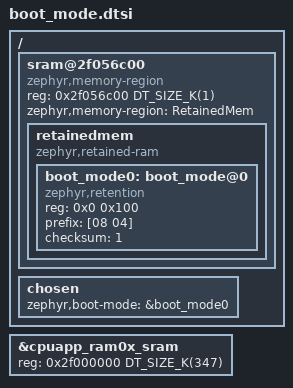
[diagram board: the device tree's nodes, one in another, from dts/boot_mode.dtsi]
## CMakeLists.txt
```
# Copyright (c) 2026 Nordic Semiconductor ASA
# SPDX-License-Identifier: LicenseRef-Nordic-5-Clause

cmake_minimum_required(VERSION 3.20.0)

find_package(Zephyr REQUIRED HINTS $ENV{ZEPHYR_BASE})
project(nrf9251_smp_single_slot)

target_sources(app PRIVATE src/main.c)
```

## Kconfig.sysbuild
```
#
# Copyright (c) 2026 Nordic Semiconductor ASA
#
# SPDX-License-Identifier: LicenseRef-Nordic-5-Clause
#

config MCUBOOT_SIGNATURE_USING_ITS
	default y if SOC_SERIES_NRF92

config BOOT_SIGNATURE_TYPE_PURE
	default y if SOC_SERIES_NRF92 && BOOT_SIGNATURE_TYPE_ED25519

choice BOOT_SIGNATURE_TYPE
	default BOOT_SIGNATURE_TYPE_ED25519 if SOC_SERIES_NRF92
endchoice

source "share/sysbuild/Kconfig"
```

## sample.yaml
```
##
# Copyright (c) 2026 Nordic Semiconductor ASA
#
# SPDX-License-Identifier: LicenseRef-Nordic-5-Clause
#

sample:
  name: nRF9251 SMP single-slot DFU sample
  description: Single-slot application update using MCUboot serial recovery over UART
common:
  sysbuild: true
  harness: console
  harness_config:
    type: one_line
    regex:
      - "nRF9251 SMP single-slot sample, firmware version"
  tags:
    - ci_samples_dfu
tests:
  sample.dfu.nrf9251_smp_single_slot:
    build_only: true
    platform_allow:
      - nrf9251dk/nrf9251/cpuapp
    integration_platforms:
      - nrf9251dk/nrf9251/cpuapp
```

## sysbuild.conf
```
# Copyright (c) 2026 Nordic Semiconductor ASA
# SPDX-License-Identifier: LicenseRef-Nordic-5-Clause

SB_CONFIG_BOOTLOADER_MCUBOOT=y
SB_CONFIG_MCUBOOT_MODE_SINGLE_APP=y

# Verify images with public keys provisioned to ITS (BL_PUBKEY slots), same as nRF54H20.
SB_CONFIG_MCUBOOT_SIGNATURE_USING_ITS=y
SB_CONFIG_BOOT_SIGNATURE_TYPE_ED25519=y
SB_CONFIG_BOOT_SIGNATURE_TYPE_PURE=y
```

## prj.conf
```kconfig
# Copyright (c) 2026 Nordic Semiconductor ASA
# SPDX-License-Identifier: LicenseRef-Nordic-5-Clause

CONFIG_BOOTLOADER_MCUBOOT=y

CONFIG_GPIO=y

CONFIG_LOG=y
CONFIG_LOG_MODE_IMMEDIATE=y

CONFIG_REBOOT=y

# Retained boot mode, shared with MCUboot via dts/boot_mode.dtsi.
CONFIG_RETAINED_MEM=y
CONFIG_RETAINED_MEM_ZEPHYR_RAM=y
CONFIG_RETENTION=y
CONFIG_RETENTION_BOOT_MODE=y

# Minimal SMP server: accept MCUmgr "os reset" with boot mode so a host MCU can
# request MCUboot serial recovery while the application is running.
# No image group: with a single slot, MCUboot serial recovery performs the update.
CONFIG_NET_BUF=y
CONFIG_ZCBOR=y
CONFIG_CRC=y
CONFIG_BASE64=y
CONFIG_MCUMGR=y
CONFIG_UART_MCUMGR=y
CONFIG_MCUMGR_TRANSPORT_UART=y
CONFIG_MCUMGR_GRP_OS=y
CONFIG_MCUMGR_GRP_OS_RESET_BOOT_MODE=y
```

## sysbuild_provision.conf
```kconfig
#
# Copyright (c) 2026 Nordic Semiconductor ASA
#
# SPDX-License-Identifier: LicenseRef-Nordic-5-Clause
#
# Optional: generate build/<app>/keyfile.json from the signing key and provision it on
# ``west flash`` (see README). Do not use in production.

SB_CONFIG_MCUBOOT_GENERATE_DEFAULT_KEY_FILE=y
```

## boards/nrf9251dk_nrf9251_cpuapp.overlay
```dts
/*
 * Copyright (c) 2026 Nordic Semiconductor ASA
 * SPDX-License-Identifier: LicenseRef-Nordic-5-Clause
 */

#include "../dts/boot_mode.dtsi"

/ {
	chosen {
		/* Same SMP UART as MCUboot serial recovery (host uses one link). */
		zephyr,uart-mcumgr = &uart132;
	};
};

&uart132 {
	status = "okay";
	memory-regions = <&cpuapp_dma_region>;
};
```

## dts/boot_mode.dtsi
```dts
/*
 * Retained-RAM boot mode region, shared by MCUboot and the application.
 *
 * Copyright (c) 2026 Nordic Semiconductor ASA
 * SPDX-License-Identifier: LicenseRef-Nordic-5-Clause
 *
 * Included from the application board overlay and the MCUboot board overlay.
 * Both images must describe this region identically.
 */

&cpuapp_ram0x_sram {
	reg = <0x2f000000 DT_SIZE_K(347)>;
	ranges = <0x0 0x2f000000 0x56c00>;
};

/ {
	sram@2f056c00 {
		compatible = "zephyr,memory-region", "mmio-sram";
		reg = <0x2f056c00 DT_SIZE_K(1)>;
		zephyr,memory-region = "RetainedMem";
		status = "okay";

		retainedmem {
			compatible = "zephyr,retained-ram";
			status = "okay";
			#address-cells = <1>;
			#size-cells = <1>;

			boot_mode0: boot_mode@0 {
				compatible = "zephyr,retention";
				status = "okay";
				reg = <0x0 0x100>;
				prefix = [08 04];
				checksum = <1>;
			};
		};
	};

	chosen {
		zephyr,boot-mode = &boot_mode0;
	};
};
```

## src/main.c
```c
/*
 * Copyright (c) 2026 Nordic Semiconductor ASA
 * SPDX-License-Identifier: LicenseRef-Nordic-5-Clause
 */

#include <zephyr/kernel.h>
#include <zephyr/device.h>
#include <zephyr/drivers/gpio.h>
#include <zephyr/logging/log.h>
#include <zephyr/devicetree.h>

LOG_MODULE_REGISTER(nrf9251_smp_single_slot, LOG_LEVEL_INF);

/* Bump when testing a firmware update over MCUboot serial recovery. */
#define APP_FW_VERSION 1

/* Version N blinks at N Hz so the rate change confirms an update. */
#define BLINK_HALF_PERIOD_MS (500 / APP_FW_VERSION)

static const struct gpio_dt_spec led = GPIO_DT_SPEC_GET(DT_ALIAS(led0), gpios);

int main(void)
{
	int err;

	LOG_INF("nRF9251 SMP single-slot sample, firmware version %d", APP_FW_VERSION);

	if (!gpio_is_ready_dt(&led)) {
		LOG_ERR("LED not ready");
		return -ENODEV;
	}

	err = gpio_pin_configure_dt(&led, GPIO_OUTPUT_INACTIVE);
	if (err != 0) {
		LOG_ERR("Failed to configure LED: %d", err);
		return err;
	}

	while (true) {
		gpio_pin_toggle_dt(&led);
		k_msleep(BLINK_HALF_PERIOD_MS);
	}

	return 0;
}
```
